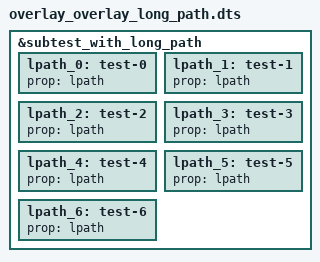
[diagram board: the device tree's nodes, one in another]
/dts-v1/;
/plugin/;

&subtest_with_long_path {
	lpath_0: test-0 {
		prop = "lpath";
	};

	lpath_1: test-1 {
		prop = "lpath";
	};

	lpath_2: test-2 {
		prop = "lpath";
	};

	lpath_3: test-3 {
		prop = "lpath";
	};

	lpath_4: test-4 {
		prop = "lpath";
	};

	lpath_5: test-5 {
		prop = "lpath";
	};

	lpath_6: test-6 {
		prop = "lpath";
	};
};
